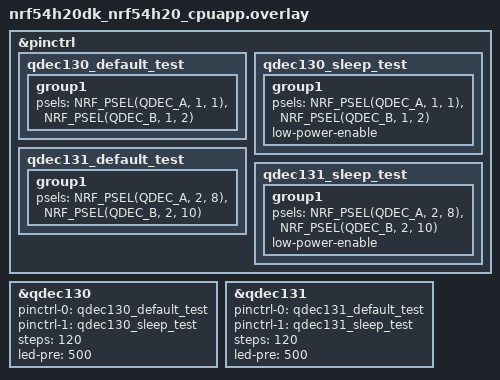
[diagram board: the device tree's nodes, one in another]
/*
 * Copyright (c) 2025 Nordic Semiconductor ASA
 *
 * SPDX-License-Identifier: LicenseRef-Nordic-5-Clause
 */

&pinctrl {
	qdec130_default_test: qdec130_default_test {
		group1 {
			psels = <NRF_PSEL(QDEC_A, 1, 1)>,
				<NRF_PSEL(QDEC_B, 1, 2)>;
		};
	};

	qdec130_sleep_test: qdec130_sleep_test {
		group1 {
			psels = <NRF_PSEL(QDEC_A, 1, 1)>,
				<NRF_PSEL(QDEC_B, 1, 2)>;
			low-power-enable;
		};
	};

	qdec131_default_test: qdec131_default_test {
		group1 {
			psels = <NRF_PSEL(QDEC_A, 2, 8)>,
				<NRF_PSEL(QDEC_B, 2, 10)>;
		};
	};

	qdec131_sleep_test: qdec131_sleep_test {
		group1 {
			psels = <NRF_PSEL(QDEC_A, 2, 8)>,
				<NRF_PSEL(QDEC_B, 2, 10)>;
			low-power-enable;
		};
	};
};

&qdec130 {
	status = "okay";
	pinctrl-0 = <&qdec130_default_test>;
	pinctrl-1 = <&qdec130_sleep_test>;
	pinctrl-names = "default", "sleep";
	steps = <120>;
	led-pre = <500>;
};

&qdec131 {
	status = "okay";
	pinctrl-0 = <&qdec131_default_test>;
	pinctrl-1 = <&qdec131_sleep_test>;
	pinctrl-names = "default", "sleep";
	steps = <120>;
	led-pre = <500>;
};
